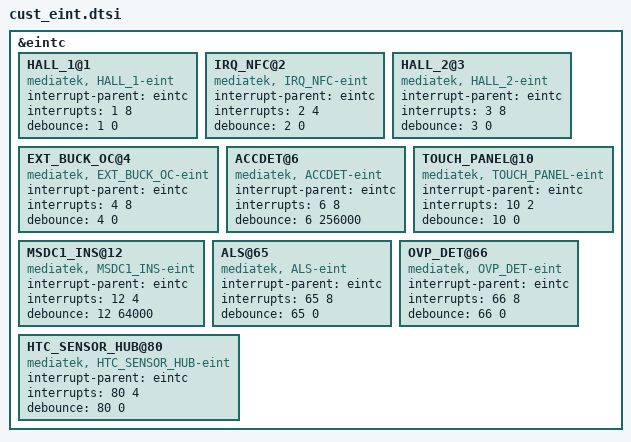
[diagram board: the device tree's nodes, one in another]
/*
 * Generated by MTK SP Drv_CodeGen Version 03.13.6  for MT6753. Copyright MediaTek Inc. (C) 2013.
 * Mon Sep  3 09:01:47 2018
 * Do Not Modify the File.
 */

/*************************
 * EINT DTSI File
*************************/

&eintc {
	HALL_1@1 {
		compatible = "mediatek, HALL_1-eint";
		interrupt-parent = <&eintc>;
		interrupts = <1 8>;
		debounce = <1 0>;
	};

	IRQ_NFC@2 {
		compatible = "mediatek, IRQ_NFC-eint";
		interrupt-parent = <&eintc>;
		interrupts = <2 4>;
		debounce = <2 0>;
	};

	HALL_2@3 {
		compatible = "mediatek, HALL_2-eint";
		interrupt-parent = <&eintc>;
		interrupts = <3 8>;
		debounce = <3 0>;
	};

	EXT_BUCK_OC@4 {
		compatible = "mediatek, EXT_BUCK_OC-eint";
		interrupt-parent = <&eintc>;
		interrupts = <4 8>;
		debounce = <4 0>;
	};

	ACCDET@6 {
		compatible = "mediatek, ACCDET-eint";
		interrupt-parent = <&eintc>;
		interrupts = <6 8>;
		debounce = <6 256000>;
	};

	TOUCH_PANEL@10 {
		compatible = "mediatek, TOUCH_PANEL-eint";
		interrupt-parent = <&eintc>;
		interrupts = <10 2>;
		debounce = <10 0>;
	};

	MSDC1_INS@12 {
		compatible = "mediatek, MSDC1_INS-eint";
		interrupt-parent = <&eintc>;
		interrupts = <12 4>;
		debounce = <12 64000>;
	};

	ALS@65 {
		compatible = "mediatek, ALS-eint";
		interrupt-parent = <&eintc>;
		interrupts = <65 8>;
		debounce = <65 0>;
	};

	OVP_DET@66 {
		compatible = "mediatek, OVP_DET-eint";
		interrupt-parent = <&eintc>;
		interrupts = <66 8>;
		debounce = <66 0>;
	};

	HTC_SENSOR_HUB@80 {
		compatible = "mediatek, HTC_SENSOR_HUB-eint";
		interrupt-parent = <&eintc>;
		interrupts = <80 4>;
		debounce = <80 0>;
	};

};
